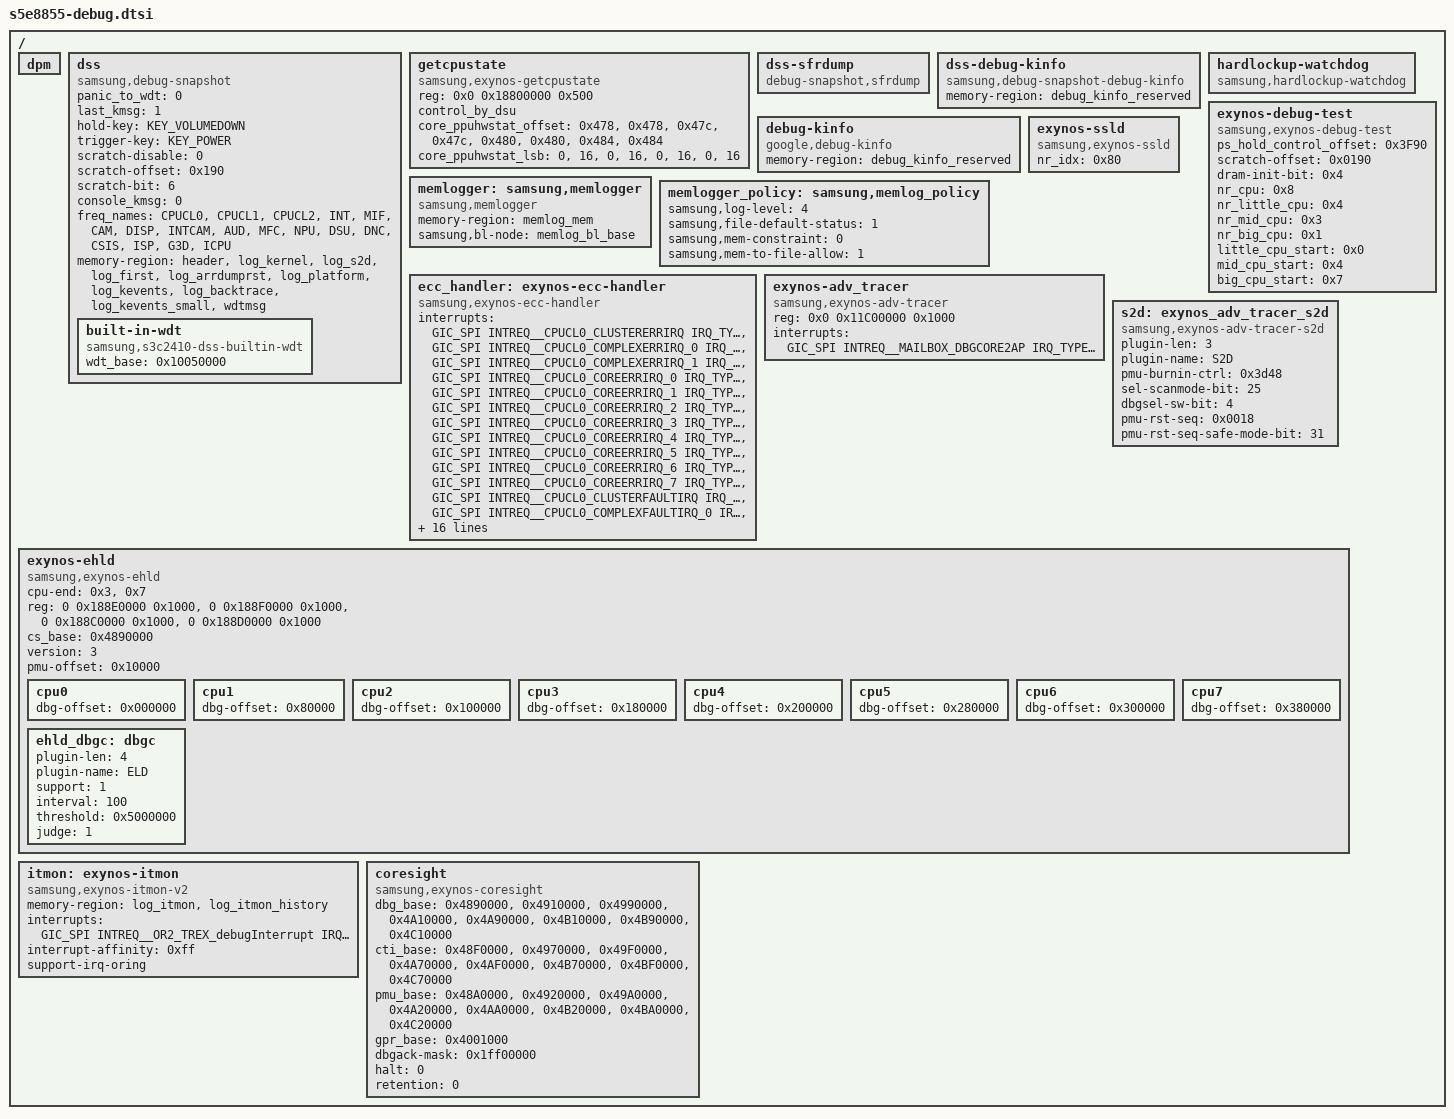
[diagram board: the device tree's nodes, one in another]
// SPDX-License-Identifier: GPL-2.0-only

#include <dt-bindings/interrupt-controller/s5e8855.h>
#include <dt-bindings/input/linux-event-codes.h>

/ {
	dpm: dpm {
	};

	dss: dss {
		compatible = "samsung,debug-snapshot";
		panic_to_wdt = <0>;
		last_kmsg = <1>;
		hold-key = <KEY_VOLUMEDOWN>;
		trigger-key = <KEY_POWER>;
		scratch-disable = <0>;
		scratch-offset = <0x190>; /* SYSIP_DAT0 */
		scratch-bit = <6>;
		console_kmsg = <0>;
		freq_names = "CPUCL0", "CPUCL1", "CPUCL2", "INT", "MIF", "CAM",
				"DISP", "INTCAM", "AUD", "MFC", "NPU", "DSU",
				"DNC", "CSIS", "ISP", "G3D", "ICPU";
		memory-region = <&header>, <&log_kernel>, <&log_s2d>,
				<&log_first>, <&log_arrdumprst>, <&log_platform>,
				<&log_kevents>, <&log_backtrace>, <&log_kevents_small>,
				<&wdtmsg>;
		built-in-wdt {
			compatible = "samsung,s3c2410-dss-builtin-wdt";
			wdt_base = <0x10050000>;
		};
	};

	getcpustate {
		compatible = "samsung,exynos-getcpustate";
		reg = <0x0 0x18800000 0x500>;
		reg-names = "dsu_base";
		control_by_dsu;
		core_ppuhwstat_offset = <0x478>, <0x478>, <0x47c>, <0x47c>,
					<0x480>, <0x480>, <0x484>, <0x484>;
		core_ppuhwstat_lsb = <0>, <16>, <0>, <16>,
				     <0>, <16>, <0>, <16>;
	};

	dss-sfrdump {
		compatible = "debug-snapshot,sfrdump";
		/* -----------<< Example >>-------------------
		dump-info {
			#address-cells = <1>;
			#size-cells = <1>;

			gic-setenable {
				reg = <0x11f01100 0x100>;
			};
			gic-setpend {
				reg = <0x11f01200 0x100>;
			};
			gic-setactive {
				reg = <0x11f01300 0x100>;
			};
		};
		*/
	};

	dss-debug-kinfo {
		compatible = "samsung,debug-snapshot-debug-kinfo";
		memory-region = <&debug_kinfo_reserved>;
	};

	debug-kinfo {
		compatible = "google,debug-kinfo";
		memory-region = <&debug_kinfo_reserved>;
	};

	hardlockup-watchdog {
		compatible = "samsung,hardlockup-watchdog";
	};

	exynos-debug-test {
		compatible = "samsung,exynos-debug-test";
		ps_hold_control_offset = <0x3F90>;
		scratch-offset = <0x0190>; /* SYSIP_DAT0 */
		dram-init-bit = <0x4>;
		nr_cpu = <0x8>;
		nr_little_cpu = <0x4>;
		nr_mid_cpu = <0x3>;
		nr_big_cpu = <0x1>;
		little_cpu_start = <0x0>;
		mid_cpu_start = <0x4>;
		big_cpu_start = <0x7>;
	};

	exynos-ssld {
		compatible = "samsung,exynos-ssld";
		nr_idx = <0x80>;
	};

	memlogger: samsung,memlogger {
		compatible = "samsung,memlogger";
		memory-region = <&memlog_mem>;
		samsung,bl-node = <&memlog_bl_base>;
	};

	memlogger_policy: samsung,memlog_policy {
		samsung,log-level = <4>;
		samsung,file-default-status = <1>;
		samsung,mem-constraint = <0>;
		samsung,mem-to-file-allow = <1>;
	};

	ecc_handler: exynos-ecc-handler {
		compatible = "samsung,exynos-ecc-handler";
		interrupts = <GIC_SPI INTREQ__CPUCL0_CLUSTERERRIRQ IRQ_TYPE_LEVEL_HIGH>,
			<GIC_SPI INTREQ__CPUCL0_COMPLEXERRIRQ_0 IRQ_TYPE_LEVEL_HIGH>,
			<GIC_SPI INTREQ__CPUCL0_COMPLEXERRIRQ_1 IRQ_TYPE_LEVEL_HIGH>,
			<GIC_SPI INTREQ__CPUCL0_COREERRIRQ_0 IRQ_TYPE_LEVEL_HIGH>,
			<GIC_SPI INTREQ__CPUCL0_COREERRIRQ_1 IRQ_TYPE_LEVEL_HIGH>,
			<GIC_SPI INTREQ__CPUCL0_COREERRIRQ_2 IRQ_TYPE_LEVEL_HIGH>,
			<GIC_SPI INTREQ__CPUCL0_COREERRIRQ_3 IRQ_TYPE_LEVEL_HIGH>,
			<GIC_SPI INTREQ__CPUCL0_COREERRIRQ_4 IRQ_TYPE_LEVEL_HIGH>,
			<GIC_SPI INTREQ__CPUCL0_COREERRIRQ_5 IRQ_TYPE_LEVEL_HIGH>,
			<GIC_SPI INTREQ__CPUCL0_COREERRIRQ_6 IRQ_TYPE_LEVEL_HIGH>,
			<GIC_SPI INTREQ__CPUCL0_COREERRIRQ_7 IRQ_TYPE_LEVEL_HIGH>,

			<GIC_SPI INTREQ__CPUCL0_CLUSTERFAULTIRQ IRQ_TYPE_LEVEL_HIGH>,
			<GIC_SPI INTREQ__CPUCL0_COMPLEXFAULTIRQ_0 IRQ_TYPE_LEVEL_HIGH>,
			<GIC_SPI INTREQ__CPUCL0_COMPLEXFAULTIRQ_1 IRQ_TYPE_LEVEL_HIGH>,
			<GIC_SPI INTREQ__CPUCL0_COREFAULTIRQ_0 IRQ_TYPE_LEVEL_HIGH>,
			<GIC_SPI INTREQ__CPUCL0_COREFAULTIRQ_1 IRQ_TYPE_LEVEL_HIGH>,
			<GIC_SPI INTREQ__CPUCL0_COREFAULTIRQ_2 IRQ_TYPE_LEVEL_HIGH>,
			<GIC_SPI INTREQ__CPUCL0_COREFAULTIRQ_3 IRQ_TYPE_LEVEL_HIGH>,
			<GIC_SPI INTREQ__CPUCL0_COREFAULTIRQ_4 IRQ_TYPE_LEVEL_HIGH>,
			<GIC_SPI INTREQ__CPUCL0_COREFAULTIRQ_5 IRQ_TYPE_LEVEL_HIGH>,
			<GIC_SPI INTREQ__CPUCL0_COREFAULTIRQ_6 IRQ_TYPE_LEVEL_HIGH>,
			<GIC_SPI INTREQ__CPUCL0_COREFAULTIRQ_7 IRQ_TYPE_LEVEL_HIGH>;
		interrupt-names = "Uncorrectable errors Cache(L3) tag RAMs or SCU snoop filter RAMs",
			"Core0-1 Complex, Uncorrectable errors on the L2 data or tag RAMs",
			"Core2-3 Complex, Uncorrectable errors on the L2 data or tag RAMs",
			"Core0, Uncorrectable errors in the L1 tag or dirty or L2 tag RAMs",
			"Core1, Uncorrectable errors in the L1 tag or dirty or L2 tag RAMs",
			"Core2, Uncorrectable errors in the L1 tag or dirty or L2 tag RAMs",
			"Core3, Uncorrectable errors in the L1 tag or dirty or L2 tag RAMs",
			"Core4, Uncorrectable errors in the L1 tag or dirty or L2 tag RAMs",
			"Core5, Uncorrectable errors in the L1 tag or dirty or L2 tag RAMs",
			"Core6, Uncorrectable errors in the L1 tag or dirty or L2 tag RAMs",
			"Core7, Uncorrectable errors in the L1 tag or dirty or L2 tag RAMs",
			"FAULTIRQ(Single bit flip 100 times) on the L3 data, tag or snoop filter RAMs",
			"Core0-1 Complex, FAULTIRQ(Single bit flip 100 times) on the L2 data or tag RAMs",
			"Core2-3 Complex, FAULTIRQ(Single bit flip 100 times) on the L2 data or tag RAMs",
			"Core0, FAULTIRQ(Single bit flip 100 times) on the L1 data or tag RAMs",
			"Core1, FAULTIRQ(Single bit flip 100 times) on the L1 data or tag RAMs",
			"Core2, FAULTIRQ(Single bit flip 100 times) on the L1 data or tag RAMs",
			"Core3, FAULTIRQ(Single bit flip 100 times) on the L1 data or tag RAMs",
			"Core4, FAULTIRQ(Single bit flip 100 times) on the L1 data or tag RAMs",
			"Core5, FAULTIRQ(Single bit flip 100 times) on the L1 data or tag RAMs",
			"Core6, FAULTIRQ(Single bit flip 100 times) on the L1 data or tag RAMs",
			"Core7, FAULTIRQ(Single bit flip 100 times) on the L1 data or tag RAMs";
		interrupt-affinity = <0xff>,
				<0x3>, <0xc>,
				<0x1>, <0x2>, <0x4>, <0x8>,
				<0x10>, <0x20>, <0x40>, <0x80>,
				<0xff>,
				<0x3>, <0xc>,
				<0x1>, <0x2>, <0x4>, <0x8>,
				<0x10>, <0x20>, <0x40>, <0x80>;
		policy = <0x0>,
				<0x0>, <0x0>,
				<0x0>, <0x0>, <0x0>, <0x0>,
				<0x0>, <0x0>, <0x0>, <0x0>,
				<0x1>,
				<0x0>, <0x0>,
				<0x0>, <0x0>, <0x0>, <0x0>,
				<0x0>, <0x0>, <0x0>, <0x0>;
	};

	exynos-adv_tracer {
		compatible = "samsung,exynos-adv-tracer";
		reg = <0x0 0x11C00000 0x1000>;
		reg-names = "mailbox";
		interrupts = <GIC_SPI INTREQ__MAILBOX_DBGCORE2AP IRQ_TYPE_LEVEL_HIGH>;
		status = "ok";
//		recovery {
//			chip_name = "s5e8845";
//			dbgc-cpu-conf = <0x3640>;
//			dbgc-cpu-status = <0x3644>;
//			rst-seq = <0x0018>;
//		};
	};

	s2d: exynos_adv_tracer_s2d {
		compatible = "samsung,exynos-adv-tracer-s2d";
		plugin-len = <3>;
		plugin-name = "S2D";
		pmu-burnin-ctrl = <0x3d48>;
		sel-scanmode-bit = <25>;
		dbgsel-sw-bit = <4>;
		pmu-rst-seq = <0x0018>;
		pmu-rst-seq-safe-mode-bit = <31>;
		status = "ok";
	};

	exynos-ehld {
		compatible = "samsung,exynos-ehld";
		status = "ok";
		cpu-end = <0x3>, <0x7>;
		reg = <0 0x188E0000 0x1000>,
			<0 0x188F0000 0x1000>,
			<0 0x188C0000 0x1000>,
			<0 0x188D0000 0x1000>;
		cs_base = <0x4890000>;
		version = <3>;
		pmu-offset = <0x10000>;
		cpu0 {
			dbg-offset = <0x000000>;
		};
		cpu1 {
			dbg-offset = <0x80000>;
		};
		cpu2 {
			dbg-offset = <0x100000>;
		};
		cpu3 {
			dbg-offset = <0x180000>;
		};
		cpu4 {
			dbg-offset = <0x200000>;
		};
		cpu5 {
			dbg-offset = <0x280000>;
		};
		cpu6 {
			dbg-offset = <0x300000>;
		};
		cpu7 {
			dbg-offset = <0x380000>;
		};

		ehld_dbgc: dbgc {
			/* IPC */
			plugin-len = <4>;
			plugin-name = "ELD";
			support = <1>;
			interval = <100>;
			threshold = <0x5000000>;
			judge = <1>;
		};
	};

	itmon: exynos-itmon {
		compatible = "samsung,exynos-itmon-v2";
		memory-region = <&log_itmon>, <&log_itmon_history>;
		interrupts = <GIC_SPI INTREQ__OR2_TREX_debugInterrupt IRQ_TYPE_LEVEL_HIGH>;
		interrupt-affinity = <0xff>;
		support-irq-oring;
		status = "ok";
	};

	coresight {
		compatible = "samsung,exynos-coresight";
		dbg_base = <0x4890000>, <0x4910000>, <0x4990000>, <0x4A10000>,
			   <0x4A90000>, <0x4B10000>, <0x4B90000>, <0x4C10000>;
		cti_base = <0x48F0000>, <0x4970000>, <0x49F0000>, <0x4A70000>,
			   <0x4AF0000>, <0x4B70000>, <0x4BF0000>, <0x4C70000>;
		pmu_base = <0x48A0000>, <0x4920000>, <0x49A0000>, <0x4A20000>,
			   <0x4AA0000>, <0x4B20000>, <0x4BA0000>, <0x4C20000>;
		gpr_base = <0x4001000>;
		dbgack-mask = <0x1ff00000>;
		halt = <0>;
		retention = <0>;
	};
};
